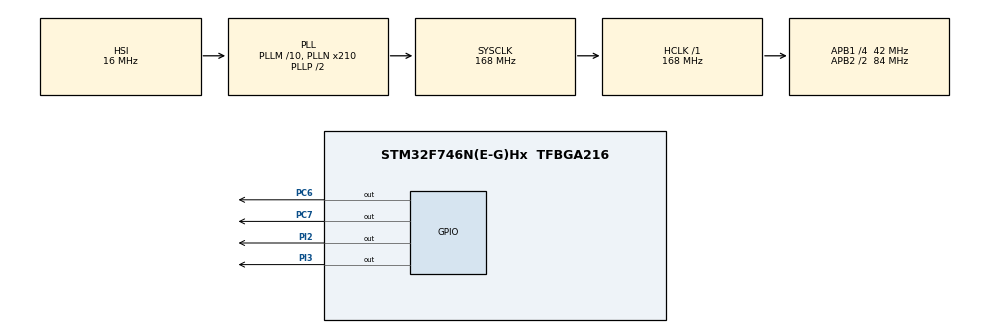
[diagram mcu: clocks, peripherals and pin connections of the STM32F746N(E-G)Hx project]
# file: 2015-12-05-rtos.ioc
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FREERTOS.Tasks01=defaultTask,0,128,StartDefaultTask
Mcu.Family=STM32F7
Mcu.Name=STM32F746N(E-G)Hx
Mcu.Package=TFBGA216
NVIC.PriorityGroup=NVIC_PRIORITYGROUP_4
PA13.Mode=Trace-Asynchronous_SW
PA13.Signal=SYS_JTMS-SWDIO
PA14.Mode=Trace-Asynchronous_SW
PA14.Signal=SYS_JTCK-SWCLK
PB3.Mode=Trace-Asynchronous_SW
PB3.Signal=SYS_JTDO-SWO
PC6.Signal=GPIO_Output
PC7.Signal=GPIO_Output
PI2.Signal=GPIO_Output
PI3.Signal=GPIO_Output
ProjectManager.TargetToolchain=SW4STM32
RCC.AHBFreq_Value=168000000
RCC.APB1CLKDivider=RCC_HCLK_DIV4
RCC.APB1Freq_Value=42000000
RCC.APB1TimFreq_Value=84000000
RCC.APB2CLKDivider=RCC_HCLK_DIV2
RCC.APB2Freq_Value=84000000
RCC.APB2TimFreq_Value=168000000
RCC.CortexFreq_Value=168000000
RCC.HCLKFreq_Value=168000000
RCC.HSE_VALUE=25000000
RCC.HSI_VALUE=16000000
RCC.LSE_VALUE=32768
RCC.PLLM=10
RCC.PLLN=210
RCC.PLLSourceVirtual=RCC_PLLSOURCE_HSI
RCC.SYSCLKFreq_VALUE=168000000
RCC.SYSCLKSource=RCC_SYSCLKSOURCE_PLLCLK
RCC.USBFreq_Value=168000000
RCC.VCOOutputFreq_Value=336000000
VP_FREERTOS_VS_ENABLE.Mode=Enabled
board=STM32F746G-DISCO

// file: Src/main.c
/**
  ******************************************************************************
  * File Name          : main.c
  * Description        : Main program body
  ******************************************************************************
  *
  * COPYRIGHT(c) 2015 STMicroelectronics
  *
  * Redistribution and use in source and binary forms, with or without modification,
  * are permitted provided that the following conditions are met:
  *   1. Redistributions of source code must retain the above copyright notice,
  *      this list of conditions and the following disclaimer.
  *   2. Redistributions in binary form must reproduce the above copyright notice,
  *      this list of conditions and the following disclaimer in the documentation
  *      and/or other materials provided with the distribution.
  *   3. Neither the name of STMicroelectronics nor the names of its contributors
  *      may be used to endorse or promote products derived from this software
  *      without specific prior written permission.
  *
  * THIS SOFTWARE IS PROVIDED BY THE COPYRIGHT HOLDERS AND CONTRIBUTORS "AS IS"
  * AND ANY EXPRESS OR IMPLIED WARRANTIES, INCLUDING, BUT NOT LIMITED TO, THE
  * IMPLIED WARRANTIES OF MERCHANTABILITY AND FITNESS FOR A PARTICULAR PURPOSE ARE
  * DISCLAIMED. IN NO EVENT SHALL THE COPYRIGHT HOLDER OR CONTRIBUTORS BE LIABLE
  * FOR ANY DIRECT, INDIRECT, INCIDENTAL, SPECIAL, EXEMPLARY, OR CONSEQUENTIAL
  * DAMAGES (INCLUDING, BUT NOT LIMITED TO, PROCUREMENT OF SUBSTITUTE GOODS OR
  * SERVICES; LOSS OF USE, DATA, OR PROFITS; OR BUSINESS INTERRUPTION) HOWEVER
  * CAUSED AND ON ANY THEORY OF LIABILITY, WHETHER IN CONTRACT, STRICT LIABILITY,
  * OR TORT (INCLUDING NEGLIGENCE OR OTHERWISE) ARISING IN ANY WAY OUT OF THE USE
  * OF THIS SOFTWARE, EVEN IF ADVISED OF THE POSSIBILITY OF SUCH DAMAGE.
  *
  ******************************************************************************
  */
#include "stm32f7xx_hal.h"
#include "cmsis_os.h"

osThreadId defaultTaskHandle;
osThreadId LED1ThreadHandle, LED2ThreadHandle;

/* USER CODE BEGIN PV */
/* Private variables ---------------------------------------------------------*/

/* USER CODE END PV */

void SystemClock_Config(void);
static void MX_GPIO_Init(void);
//void StartDefaultTask(void const * argument);
static void LED1Thread(void const *argument);
static void LED2Thread(void const *argument);

/* USER CODE BEGIN PFP */
/* Private function prototypes -----------------------------------------------*/

/* USER CODE END PFP */

int main(void)
{

  /* MCU Configuration----------------------------------------------------------*/

  /* Reset of all peripherals, Initializes the Flash interface and the Systick. */
  HAL_Init();

  /* Configure the system clock */
  SystemClock_Config();

  /* Initialize all configured peripherals */
  MX_GPIO_Init();

  /* Create the thread(s) */
  /* definition and creation of defaultTask */
  //osThreadDef(defaultTask, StartDefaultTask, osPriorityNormal, 0, 128);
  osThreadDef(LED1, LED1Thread, osPriorityLow, 0, configMINIMAL_STACK_SIZE);
  osThreadDef(LED2, LED2Thread, osPriorityLow, 0, configMINIMAL_STACK_SIZE);
  //defaultTaskHandle = osThreadCreate(osThread(defaultTask), NULL);
  LED1ThreadHandle = osThreadCreate(osThread(LED1), NULL);
  LED2ThreadHandle = osThreadCreate(osThread(LED2), NULL);
  // name, function, priority,

  /* Start scheduler */
  osKernelStart();

  /* We should never get here as control is now taken by the scheduler */

  /* Infinite loop */
  while (1)
  {

  }

}

/** System Clock Configuration
*/
void SystemClock_Config(void)
{

  RCC_OscInitTypeDef RCC_OscInitStruct;
  RCC_ClkInitTypeDef RCC_ClkInitStruct;

  __PWR_CLK_ENABLE();

  __HAL_PWR_VOLTAGESCALING_CONFIG(PWR_REGULATOR_VOLTAGE_SCALE2);

  RCC_OscInitStruct.OscillatorType = RCC_OSCILLATORTYPE_HSI;
  RCC_OscInitStruct.HSIState = RCC_HSI_ON;
  RCC_OscInitStruct.HSICalibrationValue = 16;
  RCC_OscInitStruct.PLL.PLLState = RCC_PLL_ON;
  RCC_OscInitStruct.PLL.PLLSource = RCC_PLLSOURCE_HSI;
  RCC_OscInitStruct.PLL.PLLM = 10;
  RCC_OscInitStruct.PLL.PLLN = 210;
  RCC_OscInitStruct.PLL.PLLP = RCC_PLLP_DIV2;
  RCC_OscInitStruct.PLL.PLLQ = 2;
  HAL_RCC_OscConfig(&RCC_OscInitStruct);

  RCC_ClkInitStruct.ClockType = RCC_CLOCKTYPE_HCLK|RCC_CLOCKTYPE_SYSCLK
                              |RCC_CLOCKTYPE_PCLK1|RCC_CLOCKTYPE_PCLK2;
  RCC_ClkInitStruct.SYSCLKSource = RCC_SYSCLKSOURCE_PLLCLK;
  RCC_ClkInitStruct.AHBCLKDivider = RCC_SYSCLK_DIV1;
  RCC_ClkInitStruct.APB1CLKDivider = RCC_HCLK_DIV4;
  RCC_ClkInitStruct.APB2CLKDivider = RCC_HCLK_DIV2;
  HAL_RCC_ClockConfig(&RCC_ClkInitStruct, FLASH_LATENCY_5);

  HAL_SYSTICK_Config(HAL_RCC_GetHCLKFreq()/1000);

  HAL_SYSTICK_CLKSourceConfig(SYSTICK_CLKSOURCE_HCLK);

  /* SysTick_IRQn interrupt configuration */
  HAL_NVIC_SetPriority(SysTick_IRQn, 0, 0);
}

/** Configure pins as
        * Analog
        * Input
        * Output
        * EVENT_OUT
        * EXTI
*/
void MX_GPIO_Init(void)
{

  GPIO_InitTypeDef GPIO_InitStruct;

  /* GPIO Ports Clock Enable */
  __GPIOB_CLK_ENABLE();
  __GPIOA_CLK_ENABLE();
  __GPIOI_CLK_ENABLE();
  __GPIOC_CLK_ENABLE();

  /*Configure GPIO pins : PI3 PI2 */
  GPIO_InitStruct.Pin = GPIO_PIN_3|GPIO_PIN_2;
  GPIO_InitStruct.Mode = GPIO_MODE_OUTPUT_PP;
  GPIO_InitStruct.Pull = GPIO_NOPULL;
  GPIO_InitStruct.Speed = GPIO_SPEED_LOW;
  HAL_GPIO_Init(GPIOI, &GPIO_InitStruct);

  /*Configure GPIO pins : PC7 PC6 */
  GPIO_InitStruct.Pin = GPIO_PIN_7|GPIO_PIN_6;
  GPIO_InitStruct.Mode = GPIO_MODE_OUTPUT_PP;
  GPIO_InitStruct.Pull = GPIO_NOPULL;
  GPIO_InitStruct.Speed = GPIO_SPEED_LOW;
  HAL_GPIO_Init(GPIOC, &GPIO_InitStruct);

}

/* StartDefaultTask function */
void StartDefaultTask(void const * argument)
{

  /* USER CODE BEGIN 5 */
  /* Infinite loop */
  for(;;)
  {
    osDelay(1);
	  //HAL_GPIO_TogglePin(GPIOI, GPIO_PIN_3);
	  HAL_GPIO_WritePin(GPIOI, GPIO_PIN_3, rand() % 2);
	  //HAL_Delay(rand() % 10);
	  HAL_GPIO_WritePin(GPIOC, GPIO_PIN_7, rand() % 2);
	  //HAL_GPIO_TogglePin(GPIOC, GPIO_PIN_7);
	  //HAL_Delay(rand() % 10);
  }
  /* USER CODE END 5 */
}

static void LED1Thread(void const *argument)
{
	unsigned char LED1state = 0;
	for(;;)
	{
		//HAL_GPIO_TogglePin(GPIOI, GPIO_PIN_3);
		HAL_GPIO_WritePin(GPIOI, GPIO_PIN_3, LED1state);
		osDelay(10);
		LED1state = 1;
		HAL_GPIO_WritePin(GPIOI, GPIO_PIN_3, LED1state);
		osDelay(1);
		LED1state = 0;
	}
}

static void LED2Thread(void const *argument)
{
	for(;;)
	{
		HAL_GPIO_TogglePin(GPIOC, GPIO_PIN_7);
		printf("Toggled LED2");
	}
}

/************************ (C) COPYRIGHT STMicroelectronics *****END OF FILE****/
